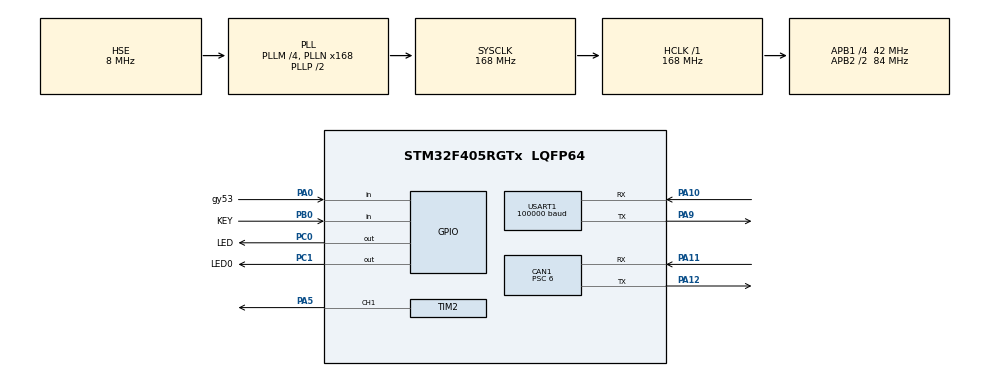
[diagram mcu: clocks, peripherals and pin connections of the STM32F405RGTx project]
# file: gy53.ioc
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CAN1.BS1=CAN_BS1_3TQ
CAN1.BS2=CAN_BS2_4TQ
CAN1.CalculateBaudRate=875000
CAN1.CalculateTimeBit=1142.85
CAN1.CalculateTimeQuantum=142.85714285714286
CAN1.Mode=CAN_MODE_NORMAL
CAN1.NART=ENABLE
CAN1.Prescaler=6
CAN1.SJW=CAN_SJW_1TQ
Dma.Request0=USART1_RX
Dma.USART1_RX.0.Direction=DMA_PERIPH_TO_MEMORY
Dma.USART1_RX.0.FIFOMode=DMA_FIFOMODE_DISABLE
Dma.USART1_RX.0.Instance=DMA2_Stream2
Dma.USART1_RX.0.MemDataAlignment=DMA_MDATAALIGN_BYTE
Dma.USART1_RX.0.MemInc=DMA_MINC_ENABLE
Dma.USART1_RX.0.Mode=DMA_NORMAL
Dma.USART1_RX.0.PeriphDataAlignment=DMA_PDATAALIGN_BYTE
Dma.USART1_RX.0.PeriphInc=DMA_PINC_DISABLE
Dma.USART1_RX.0.Priority=DMA_PRIORITY_VERY_HIGH
Mcu.Family=STM32F4
Mcu.Name=STM32F405RGTx
Mcu.Package=LQFP64
NVIC.CAN1_RX0_IRQn=true\:1\:0\:true\:false\:true\:true\:true
NVIC.DMA2_Stream2_IRQn=true\:0\:0\:false\:false\:true\:false\:true
NVIC.PriorityGroup=NVIC_PRIORITYGROUP_4
NVIC.USART1_IRQn=true\:0\:0\:false\:false\:true\:true\:true
PA0-WKUP.GPIO_Label=gy53
PA0-WKUP.GPIO_PuPd=GPIO_PULLUP
PA0-WKUP.Signal=GPIO_Input
PA10.Mode=Asynchronous
PA10.Signal=USART1_RX
PA11.Mode=CAN_Activate
PA11.Signal=CAN1_RX
PA12.Mode=CAN_Activate
PA12.Signal=CAN1_TX
PA5.Signal=S_TIM2_CH1_ETR
PA9.Mode=Asynchronous
PA9.Signal=USART1_TX
PB0.GPIO_Label=KEY
PB0.GPIO_PuPd=GPIO_PULLUP
PB0.Signal=GPIO_Input
PC0.GPIO_Label=LED
PC0.GPIO_PuPd=GPIO_PULLDOWN
PC0.GPIO_Speed=GPIO_SPEED_FREQ_HIGH
PC0.PinState=GPIO_PIN_RESET
PC0.Signal=GPIO_Output
PC1.GPIO_Label=LED0
PC1.GPIO_PuPd=GPIO_PULLDOWN
PC1.GPIO_Speed=GPIO_SPEED_FREQ_HIGH
PC1.Signal=GPIO_Output
PH0-OSC_IN.Mode=HSE-External-Oscillator
PH0-OSC_IN.Signal=RCC_OSC_IN
PH1-OSC_OUT.Mode=HSE-External-Oscillator
PH1-OSC_OUT.Signal=RCC_OSC_OUT
ProjectManager.HeapSize=0x200
ProjectManager.StackSize=0x400
ProjectManager.TargetToolchain=MDK-ARM V5.27
RCC.48MHZClocksFreq_Value=84000000
RCC.AHBFreq_Value=168000000
RCC.APB1CLKDivider=RCC_HCLK_DIV4
RCC.APB1Freq_Value=42000000
RCC.APB1TimFreq_Value=84000000
RCC.APB2CLKDivider=RCC_HCLK_DIV2
RCC.APB2Freq_Value=84000000
RCC.APB2TimFreq_Value=168000000
RCC.CortexFreq_Value=168000000
RCC.HCLKFreq_Value=168000000
RCC.HSE_VALUE=8000000
RCC.HSI_VALUE=16000000
RCC.LSE_VALUE=32768
RCC.PLLM=4
RCC.PLLN=168
RCC.PLLSourceVirtual=RCC_PLLSOURCE_HSE
RCC.SYSCLKFreq_VALUE=168000000
RCC.SYSCLKSource=RCC_SYSCLKSOURCE_PLLCLK
RCC.VCOOutputFreq_Value=336000000
SH.S_TIM2_CH1_ETR.0=TIM2_CH1,PWM Generation1 CH1
TIM2.AutoReloadPreload=TIM_AUTORELOAD_PRELOAD_ENABLE
TIM2.Channel-PWM\ Generation1\ CH1=TIM_CHANNEL_1
TIM2.Period=1000-1
TIM2.Prescaler=84-1
USART1.BaudRate=100000
USART1.Mode=MODE_RX
USART1.Parity=PARITY_EVEN
USART1.VirtualMode=VM_ASYNC
VP_IWDG_VS_IWDG.Mode=IWDG_Activate
VP_TIM2_VS_ClockSourceINT.Mode=Internal
board=custom

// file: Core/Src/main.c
/* USER CODE BEGIN Header */
/**
  ******************************************************************************
  * @file           : main.c
  * @brief          : Main program body
  ******************************************************************************
  * @attention
  *
  * <h2><center>&copy; Copyright (c) 2021 STMicroelectronics.
  * All rights reserved.</center></h2>
  *
  * This software component is licensed by ST under BSD 3-Clause license,
  * the "License"; You may not use this file except in compliance with the
  * License. You may obtain a copy of the License at:
  *                        opensource.org/licenses/BSD-3-Clause
  *
  ******************************************************************************
  */
/* USER CODE END Header */
#include "main.h"
#include "can.h"
#include "dma.h"
#include "iwdg.h"
#include "tim.h"
#include "usart.h"
#include "gpio.h"
#include "delay.h"

/* USER CODE BEGIN PV */
    uint16_t temp=0;
    uint16_t err=0;
	uint16_t distance=0;
	float time=0.0f;
/* USER CODE END PV */

void SystemClock_Config(void);

int main(void)
{

  /* MCU Configuration--------------------------------------------------------*/

  /* Reset of all peripherals, Initializes the Flash interface and the Systick. */
  HAL_Init();

  /* Configure the system clock */
  SystemClock_Config();

  /* Initialize all configured peripherals */
  MX_GPIO_Init();
  MX_DMA_Init();
  MX_CAN1_Init();
  MX_TIM2_Init();
  MX_USART1_UART_Init();
  MX_IWDG_Init();
  /* USER CODE BEGIN 2 */

	delay_init(72);
	delay_ms(500);//等待模块初始化完成
	while(HAL_GPIO_ReadPin(GPIOA,gy53_Pin) );//等待拉低

  /* USER CODE END 2 */

  /* Infinite loop */
  while (1)
  {
    while(distance<7000){
		while(!HAL_GPIO_ReadPin(GPIOA,gy53_Pin));//等待拉高开始计时
		start_Time();
		while(HAL_GPIO_ReadPin(GPIOA,gy53_Pin));//等待拉低，停止计时
		Get_Time(&time);//得到以ms为单位的时间
		temp=time*100;//距离长度=pwm时间(ms)*100
        if (temp!=0) distance=temp;
        else err++;
    }
  }
}

void SystemClock_Config(void)
{
  RCC_OscInitTypeDef RCC_OscInitStruct = {0};
  RCC_ClkInitTypeDef RCC_ClkInitStruct = {0};

  /** Configure the main internal regulator output voltage
  */
  __HAL_RCC_PWR_CLK_ENABLE();
  __HAL_PWR_VOLTAGESCALING_CONFIG(PWR_REGULATOR_VOLTAGE_SCALE1);
  /** Initializes the RCC Oscillators according to the specified parameters
  * in the RCC_OscInitTypeDef structure.
  */
  RCC_OscInitStruct.OscillatorType = RCC_OSCILLATORTYPE_LSI|RCC_OSCILLATORTYPE_HSE;
  RCC_OscInitStruct.HSEState = RCC_HSE_ON;
  RCC_OscInitStruct.LSIState = RCC_LSI_ON;
  RCC_OscInitStruct.PLL.PLLState = RCC_PLL_ON;
  RCC_OscInitStruct.PLL.PLLSource = RCC_PLLSOURCE_HSE;
  RCC_OscInitStruct.PLL.PLLM = 4;
  RCC_OscInitStruct.PLL.PLLN = 168;
  RCC_OscInitStruct.PLL.PLLP = RCC_PLLP_DIV2;
  RCC_OscInitStruct.PLL.PLLQ = 4;
  if (HAL_RCC_OscConfig(&RCC_OscInitStruct) != HAL_OK)
  {
    Error_Handler();
  }
  /** Initializes the CPU, AHB and APB buses clocks
  */
  RCC_ClkInitStruct.ClockType = RCC_CLOCKTYPE_HCLK|RCC_CLOCKTYPE_SYSCLK
                              |RCC_CLOCKTYPE_PCLK1|RCC_CLOCKTYPE_PCLK2;
  RCC_ClkInitStruct.SYSCLKSource = RCC_SYSCLKSOURCE_PLLCLK;
  RCC_ClkInitStruct.AHBCLKDivider = RCC_SYSCLK_DIV1;
  RCC_ClkInitStruct.APB1CLKDivider = RCC_HCLK_DIV4;
  RCC_ClkInitStruct.APB2CLKDivider = RCC_HCLK_DIV2;

  if (HAL_RCC_ClockConfig(&RCC_ClkInitStruct, FLASH_LATENCY_5) != HAL_OK)
  {
    Error_Handler();
  }
}

void Error_Handler(void)
{
  __disable_irq();
  while (1)
  {
  }
}

/************************ (C) COPYRIGHT STMicroelectronics *****END OF FILE****/
